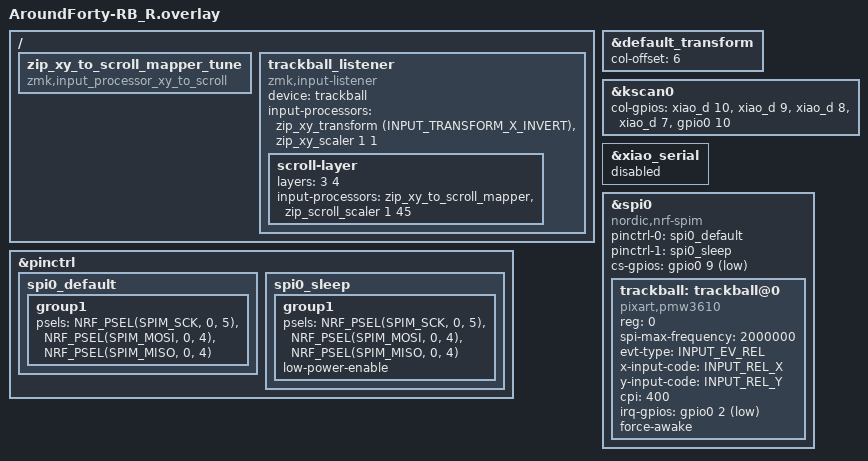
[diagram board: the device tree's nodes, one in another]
#include "AroundForty-RB.dtsi"
#include <dt-bindings/zmk/pointing.h>
#include <dt-bindings/zmk/input_transform.h>
#include <input/processors.dtsi>
#include <zephyr/dt-bindings/input/input-event-codes.h>

&default_transform {
    col-offset = <6>;
};

&kscan0 {
    col-gpios
        = <&xiao_d 10 GPIO_ACTIVE_HIGH>
        , <&xiao_d  9 GPIO_ACTIVE_HIGH>
        , <&xiao_d  8 GPIO_ACTIVE_HIGH>
        , <&xiao_d  7 GPIO_ACTIVE_HIGH>
        , <&gpio0  10 GPIO_ACTIVE_HIGH>
        ;
};


/ {
    /* スクロール方向をいつでも反転できるようにするための設定 */
    /* 反転させたい場合は compatible を "zmk,input_processor_xy_to_scroll" に変え、*/
    /* 下の scroll-layer のマッパー参照先を &zip_xy_to_scroll_mapper_tune に変更してください */
    zip_xy_to_scroll_mapper_tune: zip_xy_to_scroll_mapper_tune {
        compatible = "zmk,input_processor_xy_to_scroll";
        #input-processor-cells = <0>;
        /* 必要に応じてコメントを外して反転 */
        // scroll-y-invert;
        // scroll-x-invert;
    };

    trackball_listener: trackball_listener {
        compatible = "zmk,input-listener";
        device = <&trackball>;
        input-processors = <&zip_xy_transform (INPUT_TRANSFORM_X_INVERT)>,
                           <&zip_xy_scaler 1 1>;
                           /* AMLを有効にしたい場合は下のコメントを外してください */
                           // <&zip_temp_layer 9 300>;

        scroll-layer {
            layers = <3 4>;
            input-processors = <&zip_xy_to_scroll_mapper>, 
                               <&zip_scroll_scaler 1 45>;
        };
    };
};

&pinctrl {
    spi0_default: spi0_default {
        group1 {
            psels = <NRF_PSEL(SPIM_SCK,  0, 5)>,
                    <NRF_PSEL(SPIM_MOSI, 0, 4)>,
                    <NRF_PSEL(SPIM_MISO, 0, 4)>;
        };
    };

    spi0_sleep: spi0_sleep {
        group1 {
            psels = <NRF_PSEL(SPIM_SCK,  0, 5)>,
                    <NRF_PSEL(SPIM_MOSI, 0, 4)>,
                    <NRF_PSEL(SPIM_MISO, 0, 4)>;
            low-power-enable;
        };
    };
};

&xiao_serial { status = "disabled"; };

&spi0 {
    status = "okay";
    compatible = "nordic,nrf-spim";
    pinctrl-0 = <&spi0_default>;
    pinctrl-1 = <&spi0_sleep>;
    pinctrl-names = "default", "sleep";
    cs-gpios = <&gpio0 9 GPIO_ACTIVE_LOW>;

    trackball: trackball@0 {
        status = "okay";
        compatible = "pixart,pmw3610";
        reg = <0>;
        spi-max-frequency = <2000000>;
        evt-type = <INPUT_EV_REL>;
        x-input-code = <INPUT_REL_X>;
        y-input-code = <INPUT_REL_Y>;
        cpi = <400>;
        irq-gpios = <&gpio0 2 (GPIO_ACTIVE_LOW | GPIO_PULL_UP)>;
        force-awake;
    };
};
